# LPC844 register map
Vendor: nxp.com; File version: 1.0
CPU: CM0PLUS r0p0, little endian, no MPU, no FPU, VTOR, 2 interrupt priority bits
Registers are 32-bit, read-write, reset 0x0 unless marked. A register's access mark holds for its fields unless they carry their own. Offsets are from the block's base; [hi:lo] are bit positions; lines under a group give offsets from that group; {n}, {i} and the like mark numbered series; 'fields as' and 'values as' point back to an identical list.

## SYSCON — LPC84x System configuration (SYSCON)
Base 0x40048000
0x00 SYSMEMREMAP — System Remap register
  [1:0] MAP — System memory remap. Value 0x3 is reserved.
    0=BOOT_LOADER_MODE (Boot Loader Mode. Interrupt vectors are re-mapped to Boot ROM.); 1=USER_RAM_MODE (User RAM Mode. Interrupt vectors are re-mapped to Static RAM.); 2=USER_FLASH_MODE (User Flash Mode. Interrupt vectors are not re-mapped and reside in Flash.)
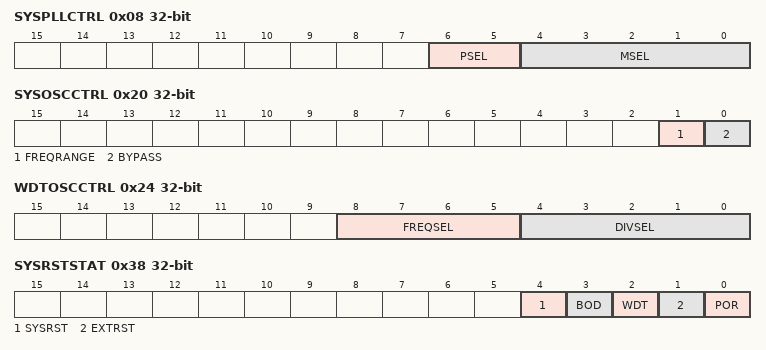
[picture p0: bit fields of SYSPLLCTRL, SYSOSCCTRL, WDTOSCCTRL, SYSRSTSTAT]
0x08 SYSPLLCTRL — PLL control
  [6:5] PSEL — Post divider ratio P. The division ratio is 2 x P.
    0=P = 1; 1=P = 2; 2=P = 4; 3=P = 8
  [4:0] MSEL — Feedback divider value. The division value M is the programmed MSEL value + 1. 00000: Division ratio M = 1 to 11111: Division ratio M = 32
0x0C SYSPLLSTAT ro — PLL status
  [0] LOCK — PLL0 lock indicator
0x20 SYSOSCCTRL — system oscillator control
  [1] FREQRANGE — oscillator low / high transconductance selection input (Active High) 1-20MHz '0' : 15-50MHz '1'
  [0] BYPASS — oscillator (Xtal) Test Mode input (Active High)
0x24 WDTOSCCTRL — Watchdog oscillator control
  [8:5] FREQSEL — Frequency select. Selects the frequency of the oscillator. 0x00 = invalid setting when watchdog oscillator is running 0x1 = 0.6 MHz 0x2 = 1.05 MHz 0x3 = 1.4 MHz 0x4 = 1.75 MHz 0x5 = 2.1 MHz 0x6 = 2.4 MHz 0x7 = 2.7 MHz 0x8 = 3.0 MHz 0x9 = 3.25 MHz 0xA = 3.5 MHz 0xB = 3.75 MHz 0xC = 4.0 MHz 0xD = 4.2 MHz 0xE = 4.4 MHz 0xF = 4.6 MHz
  [4:0] DIVSEL — Select divider for Fclkana. wdt_osc_clk = Fclkana/ (2 x (1 + DIVSEL)) 00000: 2 x (1 + DIVSEL) = 2 00001: 2 x (1 + DIVSEL) = 4 to 11111: 2 x (1 + DIVSEL) = 64
0x28 FROOSCCTRL — FRO oscillator control
  [17] FRO_DIRECT — fro direct clock select
    0=DISABLED (fro clock is divider by 2 or 16,depend on FAIM slow boot value); 1=ENABLED (fro clock is direct from FRO oscillator)
0x30 FRODIRECTCLKUEN — FRO direct clock source update enable register
  [0] ENA — Enable fro clock source update
    0=NO_CHANGE; 1=UPDATED (update clock source)
0x38 SYSRSTSTAT — System reset status register
  [4] SYSRST — Status of the software system reset
    0=NO_DETECTED (No System reset detected); 1=DETECTED (System reset detected. Writing a one clears this reset.)
  [3] BOD — Status of the Brown-out detect reset
    0=NO_DETECTED (No BOD reset detected); 1=DETECTED (BOD reset detected. Writing a one clears this reset.)
  [2] WDT — Status of the Watchdog reset
    0=NO_DETECTED (No WDT reset detected); 1=DETECTED (WDT reset detected. Writing a one clears this reset.)
  [1] EXTRST — Status of the external RESET pin. External reset status.
    0=NO_DETECTED (No reset event detected.); 1=DETECTED (Reset detected. Writing a one clears this reset.)
  [0] POR — POR reset status
    0=NO_DETECTED (No POR detected); 1=DETECTED (POR detected. Writing a one clears this reset.)
0x40 SYSPLLCLKSEL — System PLL clock source select register
  [1:0] SEL — System PLL clock source
    0=FRO; 1=EXT_CLK (External clock); 2=WDTOSC (Watchdog oscillator); 3=FRODIV
0x44 SYSPLLCLKUEN — System PLL clock source update enable register
  [0] ENA — Enable system PLL clock source update
    0=NO_CHANGE; 1=UPDATED (update clock source)
0x48 MAINCLKPLLSEL — Main clock source select register
  [1:0] SEL — System PLL clock source
    0=MAIN_CLK_PRE_PLL; 1=SYS_PLL; 2=none; 3=none
0x4C MAINCLKPLLUEN — Main clock source update enable register
  [0] ENA — Enable main clock source update
    0=NO_CHANGE; 1=UPDATED (update clock source)
0x50 MAINCLKSEL — Main clock source select register
  [1:0] SEL — System PLL clock source
    0=FRO; 1=EXT_CLK (External clock); 2=WDTOSC (Watchdog oscillator); 3=FRO_DIV
0x54 MAINCLKUEN — Main clock source update enable register
  fields as MAINCLKPLLUEN
0x58 SYSAHBCLKDIV reset 0x1 — System clock divider register
  [7:0] DIV — System AHB clock divider values 0: System clock disabled. 1: Divide by 1. to 255: Divide by 255.
0x60 CAPTCLKSEL reset 0x7 — CAPT clock source select register
  [2:0] SEL — Clock source for CAPT clock
    0=FRO; 1=MAIN_CLK (main clock); 2=SYS_PLL; 3=FRO_DIV; 4=WDTOSC (Watchdog oscillator); 5=NONE; 6=NONE1; 7=NONE2
0x64 ADCCLKSEL — ADC clock source select register
  [1:0] SEL — Clock source for ADC clock
    0=FRO; 1=SYS_PLL; 2=NONE; 3=NONE1
0x68 ADCCLKDIV — ADC clock divider register
  [7:0] DIV — ADC clock divider values 0: ADC clock disabled. 1: Divide by 1. to 255: Divide by 255.
0x6C SCTCLKSEL — SCT clock source select register
  [1:0] SEL — Clock source for SCT clock
    0=FRO; 1=MAIN_CLK (main clock); 2=SYS_PLL; 3=NONE
0x70 SCTCLKDIV — SCT clock divider register
  [7:0] DIV — SCT clock divider values 0: SCT clock disabled. 1: Divide by 1. to 255: Divide by 255.
0x74 EXTCLKSEL — external clock source select register
  [0] SEL — Clock source for external clock
    0=SYS_OSC (System oscillator); 1=CLK_IN
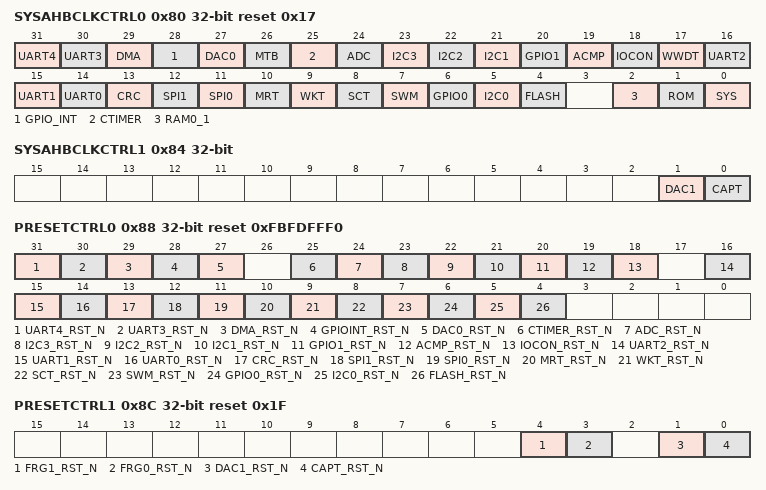
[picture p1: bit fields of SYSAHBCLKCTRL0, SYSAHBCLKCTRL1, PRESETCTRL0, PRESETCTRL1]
0x80 SYSAHBCLKCTRL0 reset 0x17 — System clock group 0 control register
  [31] UART4 — Enables clock for UART4.
    0=DISABLE; 1=ENABLE
  [30] UART3 — Enables clock for UART3.
    0=DISABLE; 1=ENABLE
  [29] DMA — Enables clock for DMA.
    0=DISABLE; 1=ENABLE
  [28] GPIO_INT — Enable clock for GPIO pin interrupt registers
    0=DISABLE; 1=ENABLE
  [27] DAC0 — Enables clock for DAC0.
    0=DISABLE; 1=ENABLE
  [26] MTB — Enables clock to micro-trace buffer control registers. Turn on this clock when using the micro-trace buffer for debug purposes.
    0=DISABLE; 1=ENABLE
  [25] CTIMER — Enables clock for CTIMER.
    0=DISABLE; 1=ENABLE
  [24] ADC — Enables clock for ADC.
    0=DISABLE; 1=ENABLE
  [23] I2C3 — Enables clock for I2C3.
    0=DISABLE; 1=ENABLE
  [22] I2C2 — Enables clock for I2C2.
    0=DISABLE; 1=ENABLE
  [21] I2C1 — Enables clock for I2C1.
    0=DISABLE; 1=ENABLE
  [20] GPIO1 — Enables clock for GPIO1 port registers.
    0=DISABLE; 1=ENABLE
  [19] ACMP — Enables clock for analog comparator.
    0=DISABLE; 1=ENABLE
  [18] IOCON — Enables clock for IOCON.
    0=DISABLE; 1=ENABLE
  [17] WWDT — Enables clock for WWDT.
    0=DISABLE; 1=ENABLE
  [16] UART2 — Enables clock for UART2.
    0=DISABLE; 1=ENABLE
  [15] UART1 — Enables clock for UART1.
    0=DISABLE; 1=ENABLE
  [14] UART0 — Enables clock for UART0.
    0=DISABLE; 1=ENABLE
  [13] CRC — Enables clock for CRC.
    0=DISABLE; 1=ENABLE
  [12] SPI1 — Enables clock for SPI1.
    0=DISABLE; 1=ENABLE
  [11] SPI0 — Enables clock for SPI0.
    0=DISABLE; 1=ENABLE
  [10] MRT — Enables clock for multi-rate timer.
    0=DISABLE; 1=ENABLE
  [9] WKT — Enables clock for self-wake-up timer.
    0=DISABLE; 1=ENABLE
  [8] SCT — Enables clock for state configurable timer SCTimer/PWM.
    0=DISABLE; 1=ENABLE
  [7] SWM — Enables clock for switch matrix.
    0=DISABLE; 1=ENABLE
  [6] GPIO0 — Enables clock for GPIO0 port registers.
    0=DISABLE; 1=ENABLE
  [5] I2C0 — Enables clock for I2C0.
    0=DISABLE; 1=ENABLE
  [4] FLASH — Enables clock for flash.
    0=DISABLE; 1=ENABLE
  [2] RAM0_1 — Enables clock for SRAM0 and SRAM1.
    0=DISABLE; 1=ENABLE
  [1] ROM — Enables clock for ROM.
    0=DISABLE; 1=ENABLE
  [0] SYS — Enables the clock for the AHB, the APB bridge, the Cortex-M0+ core clocks, SYSCON, and the PMU. This bit is read only and always reads as 1.
0x84 SYSAHBCLKCTRL1 — System clock group 1 control register
  [1] DAC1 — Enables clock for DAC1.
    0=DISABLE; 1=ENABLE
  [0] CAPT — Enables clock for CAPT.
    0=DISABLE; 1=ENABLE
0x88 PRESETCTRL0 reset 0xFBFDFFF0 — Peripheral reset group 0 control register
  [31] UART4_RST_N — UART4 reset control
    0=ASSERT (Assert the UART4 reset.); 1=CLEAR (Clear the UART4 reset.)
  [30] UART3_RST_N — UART3 reset control
    0=ASSERT (Assert the UART3 reset.); 1=CLEAR (Clear the UART3 reset.)
  [29] DMA_RST_N — DMA reset control
    0=ASSERT (Assert the DMA reset.); 1=CLEAR (Clear the DMA reset.)
  [28] GPIOINT_RST_N — GPIOINT reset control
    0=ASSERT (Assert the GPIOINT reset.); 1=CLEAR (Clear the GPIOINT reset.)
  [27] DAC0_RST_N — DAC0 reset control
    0=ASSERT (Assert the DAC0 reset.); 1=CLEAR (Clear the DAC0 reset.)
  [25] CTIMER_RST_N — CTIMER reset control
    0=ASSERT (Assert the CTIMER reset.); 1=CLEAR (Clear the CTIMER reset.)
  [24] ADC_RST_N — ADC reset control
    0=ASSERT (Assert the ADC reset.); 1=CLEAR (Clear the ADC reset.)
  [23] I2C3_RST_N — I2C3 reset control
    0=ASSERT (Assert the I2C3 reset.); 1=CLEAR (Clear the I2C3 reset.)
  [22] I2C2_RST_N — I2C2 reset control
    0=ASSERT (Assert the I2C2 reset.); 1=CLEAR (Clear the I2C2 reset.)
  [21] I2C1_RST_N — I2C1 reset control
    0=ASSERT (Assert the I2C1 reset.); 1=CLEAR (Clear the I2C1 reset.)
  [20] GPIO1_RST_N — GPIO1 reset control
    0=ASSERT (Assert the GPIO1 reset.); 1=CLEAR (Clear the GPIO1 reset.)
  [19] ACMP_RST_N — Analog comparator reset control
    0=ASSERT (Assert the analog comparator reset.); 1=CLEAR (Clear the analog comparator reset.)
  [18] IOCON_RST_N — IOCON reset control
    0=ASSERT (Assert the IOCON reset.); 1=CLEAR (Clear the IOCON reset.)
  [16] UART2_RST_N — UART2 reset control
    0=ASSERT (Assert the UART2 reset.); 1=CLEAR (Clear the UART2 reset.)
  [15] UART1_RST_N — UART1 reset control
    0=ASSERT (Assert the UART1 reset.); 1=CLEAR (Clear the UART1 reset.)
  [14] UART0_RST_N — UART0 reset control
    0=ASSERT (Assert the UART0 reset.); 1=Clear the UART0 reset
  [13] CRC_RST_N — CRC engine reset control
    0=ASSERT (Assert the CRC reset.); 1=CLEAR (Clear the CRC reset.)
  [12] SPI1_RST_N — SPI1 reset control
    0=ASSERT (Assert the SPI1 reset.); 1=CLEAR (Clear the SPI1 reset.)
  [11] SPI0_RST_N — SPI0 reset control
    0=ASSERT (Assert the SPI0 reset.); 1=CLEAR (Clear the SPI0 reset.)
  [10] MRT_RST_N — Multi-rate timer (MRT) reset control
    0=ASSERT (Assert the MRT reset.); 1=CLEAR (Clear the MRT reset.)
  [9] WKT_RST_N — Self-wake-up timer (WKT) reset control
    0=ASSERT (Assert the WKT reset.); 1=CLEAR (Clear the WKT reset.)
  [8] SCT_RST_N — SCT reset control
    0=ASSERT (Assert the SCT reset.); 1=CLEAR (Clear the SCT reset.)
  [7] SWM_RST_N — SWM reset control
    0=ASSERT (Assert the SWM reset.); 1=CLEAR (Clear the SWM reset.)
  [6] GPIO0_RST_N — GPIO0 reset control
    0=ASSERT (Assert the GPIO0 reset.); 1=CLEAR (Clear the GPIO0 reset.)
  [5] I2C0_RST_N — I2C0 reset control
    0=ASSERT (Assert the I2C0 reset.); 1=CLEAR (Clear the I2C0 reset.)
  [4] FLASH_RST_N — flash controller reset control
    0=ASSERT (Assert the flash controller reset.); 1=CLEAR (Clear the flash controller reset.)
0x8C PRESETCTRL1 reset 0x1F — Peripheral reset group 1 control register
  [4] FRG1_RST_N — Fractional baud rate generator 1 reset control
    0=ASSERT (Assert the FRG1 reset.); 1=CLEAR (Clear the FRG1 reset.)
  [3] FRG0_RST_N — Fractional baud rate generator 0 reset control
    0=ASSERT (Assert the FRG0 reset.); 1=CLEAR (Clear the FRG0 reset.)
  [1] DAC1_RST_N — DAC1 reset control
    0=ASSERT (Assert the DAC1 reset.); 1=CLEAR (Clear the DAC1 reset.)
  [0] CAPT_RST_N — Capacitive touch reset control
    0=ASSERT (Assert the capacitive touch reset.); 1=CLEAR (Clear the capacitive touch reset.)
{0x90+4i} FCLKSEL[{i}] (i=0..10) reset 0x7 — peripheral clock source select register. FCLK0SEL~FCLK4SEL are for UART0~UART4 clock source select register. FCLK5SEL~FCLK8SEL are for I2C0~I2C3 clock source select register. FCLK9SEL~FCLK10SEL are for SPI0~SPI1 clock source select register.
  [2:0] SEL — Peripheral clock source
    0=FRO; 1=MAIN_CLK (main clock); 2=FRG0CLK; 3=FRG1CLK; 4=FRO_DIV; 5=NONE; 6=NONE1; 7=NONE2
{0xD0+0x10*i} FRG[{i}] (i=0..1) group
  0x00 FRGDIV — fractional generator N divider value register
    [7:0] DIV — Denominator of the fractional divider. DIV is equal to the programmed value +1. Always set to 0xFF to use with the fractional baud rate generator.
  0x04 FRGMULT — fractional generator N multiplier value register
    [7:0] MULT — Numerator of the fractional divider. MULT is equal to the programmed value.
  0x08 FRGCLKSEL — FRG N clock source select register
    [1:0] SEL — Clock source for frgN_src clock
      0=FRO; 1=MAIN_CLK (main clock); 2=SYS_PLL; 3=NONE
0xF0 CLKOUTSEL — CLKOUT clock source select register
  [2:0] SEL — CLKOUT clock source
    0=FRO; 1=MAIN_CLK (main clock); 2=SYS_PLL; 3=EXT_CLK (external clock); 4=WDTOSC (Watchdog oscillator); 5=NONE; 6=NONE1; 7=NONE2
0xF4 CLKOUTDIV — CLKOUT clock divider registers
  [7:0] DIV — CLKOUT clock divider values 0: Disable CLKOUT clock divider. 1: Divide by 1. to 255: Divide by 255.
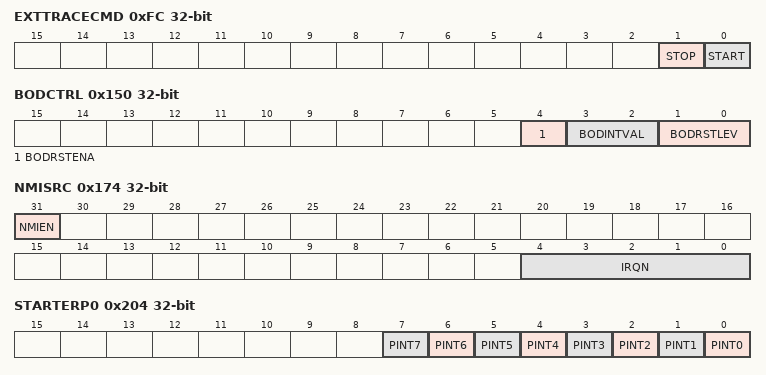
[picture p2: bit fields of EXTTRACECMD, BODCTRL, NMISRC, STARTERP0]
0xFC EXTTRACECMD — External trace buffer command register
  [1] STOP — Trace stop command. Writing a one to this bit sets the TSTOP signal in the MTB to HIGH and stops tracing if the TSTOPEN bit in the MTB master register is set to one as well.
  [0] START — Trace start command. Writing a one to this bit sets the TSTART signal to the MTB to HIGH and starts tracing if the TSTARTEN bit in the MTB master register is set to one as well.
{0x100+4i} PIOPORCAP[{i}] (i=0..1) ro reset not defined — POR captured PIO N status register(PIO0 has 32 PIOs, PIO1 has 22 PIOs)
  [31:0] PIOSTAT — State of PION_31 through PION_0 at power-on reset
0x134 IOCONCLKDIV6 — Peripheral clock 6 to the IOCON block for programmable glitch filter
  [7:0] DIV — IOCON glitch filter clock divider values 0: Disable IOCONFILTR_PCLK. 1: Divide by 1. to 255: Divide by 255.
0x138 IOCONCLKDIV5 — Peripheral clock 6 to the IOCON block for programmable glitch filter
  fields as IOCONCLKDIV6
0x13C IOCONCLKDIV4 — Peripheral clock 4 to the IOCON block for programmable glitch filter
  fields as IOCONCLKDIV6
0x140 IOCONCLKDIV3 — Peripheral clock 3 to the IOCON block for programmable glitch filter
  fields as IOCONCLKDIV6
0x144 IOCONCLKDIV2 — Peripheral clock 2 to the IOCON block for programmable glitch filter
  fields as IOCONCLKDIV6
0x148 IOCONCLKDIV1 — Peripheral clock 1 to the IOCON block for programmable glitch filter
  fields as IOCONCLKDIV6
0x14C IOCONCLKDIV0 — Peripheral clock 0 to the IOCON block for programmable glitch filter
  fields as IOCONCLKDIV6
0x150 BODCTRL — BOD control register
  [4] BODRSTENA — BOD reset enable
    0=DISABLE (Disable reset function.); 1=ENABLE (Enable reset function.)
  [3:2] BODINTVAL — BOD interrupt level
    1=LEVEL_1; 2=LEVEL_2; 3=LEVEL_3
  [1:0] BODRSTLEV — BOD reset level
    1=LEVEL_1; 2=LEVEL_2; 3=LEVEL_3
0x154 SYSTCKCAL — System tick timer calibration register
  [25:0] CAL — System tick timer calibration value.
0x170 IRQLATENCY reset 0x10
  [7:0] LATENCY — 8-bit latency value.
0x174 NMISRC — NMI source selection register
  [31] NMIEN — Write a 1 to this bit to enable the Non-Maskable Interrupt (NMI) source selected by bits 4:0.
  [4:0] IRQN — The IRQ number of the interrupt that acts as the Non-Maskable Interrupt (NMI) if bit 31 is 1
{0x178+4i} PINTSEL[{i}] (i=0..7) — Pin interrupt select registers N
  [5:0] INTPIN — Pin number select for pin interrupt or pattern match engine input. (PIO0_0 to PIO0_31correspond to numbers 0 to 31 and PIO1_0 to PIO1_31 correspond to numbers 32 to 63).
0x204 STARTERP0 — Start logic 0 pin wake-up enable register 0
  [all] fields
    0=DISABLED; 1=ENABLED
  [n] PINT{n} (n=0..7) — GPIO pin interrupt {n} wake-up
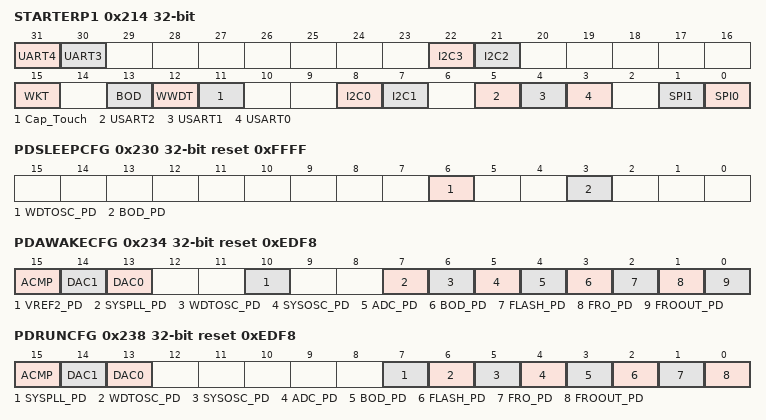
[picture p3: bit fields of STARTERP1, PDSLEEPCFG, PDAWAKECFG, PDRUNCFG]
0x214 STARTERP1 (reset mask 0xFF) — Start logic 0 pin wake-up enable register 1
  [all] fields
    0=DISABLED; 1=ENABLED
  [31] UART4 — UART4 interrupt wake-up
  [30] UART3 — UART3 interrupt wake-up
  [22] I2C3 — I2C3 interrupt wake-up
  [21] I2C2 — I2C2 interrupt wake-up
  [15] WKT — Self-wake-up timer interrupt wake-up
  [13] BOD — BOD interrupt wake-up
  [12] WWDT — WWDT interrupt wake-up
  [11] Cap_Touch — Cap Touch interrupt wake-up.
  [8] I2C0 — I2C0 interrupt wake-up.
  [7] I2C1 — I2C1 interrupt wake-up.
  [5] USART2 — USART2 interrupt wake-up. Configure USART in synchronous slave mode.
  [4] USART1 — USART1 interrupt wake-up. Configure USART in synchronous slave mode.
  [3] USART0 — USART0 interrupt wake-up. Configure USART in synchronous slave mode.
  [1] SPI1 — SPI1 interrupt wake-up
  [0] SPI0 — SPI0 interrupt wake-up
0x230 PDSLEEPCFG reset 0xFFFF — Deep-sleep configuration register
  [6] WDTOSC_PD — Watchdog oscillator power-down control for Deep-sleep and Power-down mode. Changing this bit to powered-down has no effect when the LOCK bit in the WWDT MOD register is set. In this case, the watchdog oscillator is always running.
    0=DISABLED; 1=ENABLED
  [3] BOD_PD — BOD power-down control for Deep-sleep and Power-down mode
    0=POWERED; 1=POWERED_DOWN
0x234 PDAWAKECFG reset 0xEDF8 — Wake-up configuration register
  [15] ACMP — Analog comparator wake-up configuration
    0=DISABLED; 1=ENABLED
  [14] DAC1 — DAC1 wake-up configuration
    0=DISABLED; 1=ENABLED
  [13] DAC0 — DAC0 wake-up configuration
    0=DISABLED; 1=ENABLED
  [10] VREF2_PD — VREF2 wake-up configuration
    0=DISABLED; 1=ENABLED
  [7] SYSPLL_PD — System PLL wake-up configuration
    0=DISABLED; 1=ENABLED
  [6] WDTOSC_PD — Watchdog oscillator wake-up configuration. Changing this bit to powered-down has no effect when the LOCK bit in the WWDT MOD register is set. In this case, the watchdog oscillator is always running
    0=DISABLED; 1=ENABLED
  [5] SYSOSC_PD — Crystal oscillator wake-up configuration
    0=POWERED; 1=POWERED_DOWN
  [4] ADC_PD — ADC wake-up configuration
    0=POWERED; 1=POWERED_DOWN
  [3] BOD_PD — BOD wake-up configuration
    0=POWERED; 1=POWERED_DOWN
  [2] FLASH_PD — Flash wake-up configuration
    0=POWERED; 1=POWERED_DOWN
  [1] FRO_PD — FRO oscillator power-down wake-up configuration
    0=POWERED; 1=POWERED_DOWN
  [0] FROOUT_PD — FRO oscillator output wake-up configuration
    0=POWERED; 1=POWERED_DOWN
0x238 PDRUNCFG reset 0xEDF8 — Power configuration register
  [15] ACMP — Analog comparator wake-up configuration
    0=DISABLED; 1=ENABLED
  [14] DAC1 — DAC1 wake-up configuration
    0=DISABLED; 1=ENABLED
  [13] DAC0 — DAC0 wake-up configuration
    0=DISABLED; 1=ENABLED
  [7] SYSPLL_PD — System PLL wake-up configuration
    0=DISABLED; 1=ENABLED
  [6] WDTOSC_PD — Watchdog oscillator wake-up configuration. Changing this bit to powered-down has no effect when the LOCK bit in the WWDT MOD register is set. In this case, the watchdog oscillator is always running
    0=DISABLED; 1=ENABLED
  [5] SYSOSC_PD — Crystal oscillator wake-up configuration
    0=POWERED; 1=POWERED_DOWN
  [4] ADC_PD — ADC wake-up configuration
    0=POWERED; 1=POWERED_DOWN
  [3] BOD_PD — BOD wake-up configuration
    0=POWERED; 1=POWERED_DOWN
  [2] FLASH_PD — Flash wake-up configuration
    0=POWERED; 1=POWERED_DOWN
  [1] FRO_PD — FRO oscillator power-down wake-up configuration
    0=POWERED; 1=POWERED_DOWN
  [0] FROOUT_PD — FRO oscillator output wake-up configuration
    0=POWERED; 1=POWERED_DOWN
0x3F8 DEVICE_ID ro — Part ID register
  [31:0] DEVICEID — Part ID
